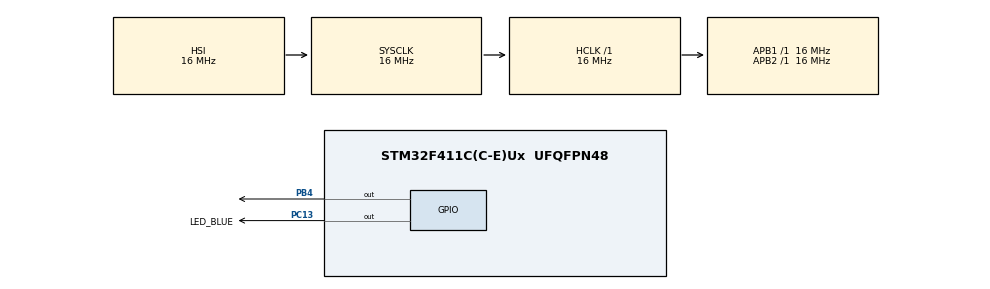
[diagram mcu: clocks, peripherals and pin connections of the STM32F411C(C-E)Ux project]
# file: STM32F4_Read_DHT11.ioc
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Mcu.Family=STM32F4
Mcu.Name=STM32F411C(C-E)Ux
Mcu.Package=UFQFPN48
NVIC.PriorityGroup=NVIC_PRIORITYGROUP_4
PA13.Mode=Serial_Wire
PA13.Signal=SYS_JTMS-SWDIO
PA14.Mode=Serial_Wire
PA14.Signal=SYS_JTCK-SWCLK
PB4.GPIO_ModeDefaultOutputPP=GPIO_MODE_OUTPUT_PP
PB4.GPIO_PuPd=GPIO_NOPULL
PB4.Signal=GPIO_Output
PC13-ANTI_TAMP.GPIO_Label=LED_BLUE
PC13-ANTI_TAMP.Signal=GPIO_Output
PH0\ -\ OSC_IN.Mode=HSE-External-Oscillator
PH0\ -\ OSC_IN.Signal=RCC_OSC_IN
PH1\ -\ OSC_OUT.Mode=HSE-External-Oscillator
PH1\ -\ OSC_OUT.Signal=RCC_OSC_OUT
ProjectManager.HeapSize=0x200
ProjectManager.StackSize=0x400
ProjectManager.TargetToolchain=STM32CubeIDE
RCC.AHBFreq_Value=16000000
RCC.APB1Freq_Value=16000000
RCC.APB2Freq_Value=16000000
RCC.CortexFreq_Value=16000000
RCC.HSE_VALUE=25000000
RCC.HSI_VALUE=16000000
RCC.LSE_VALUE=32768
RCC.SYSCLKFreq_VALUE=16000000
RCC.VCOOutputFreq_Value=192000000
TIM2.Period=0xffffffff
TIM2.Prescaler=15
VP_TIM2_VS_ClockSourceINT.Mode=Internal
board=custom

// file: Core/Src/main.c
/* USER CODE BEGIN Header */
/**
  ******************************************************************************
  * @file           : main.c
  * @brief          : Main program body
  ******************************************************************************
  * @attention
  *
  * Copyright (c) 2025 STMicroelectronics.
  * All rights reserved.
  *
  * This software is licensed under terms that can be found in the LICENSE file
  * in the root directory of this software component.
  * If no LICENSE file comes with this software, it is provided AS-IS.
  *
  ******************************************************************************
  */
/* USER CODE END Header */
#include "main.h"
#include "DHT11.h"

TIM_HandleTypeDef htim2;

/* USER CODE BEGIN PV */
volatile int32_t temperature = 0;
dht11_t dht11_sensor;
/* USER CODE END PV */

void SystemClock_Config(void);
static void MX_GPIO_Init(void);
static void MX_TIM2_Init(void);

int main(void)
{

  /* MCU Configuration--------------------------------------------------------*/

  /* Reset of all peripherals, Initializes the Flash interface and the Systick. */
  HAL_Init();

  /* Configure the system clock */
  SystemClock_Config();

  /* Initialize all configured peripherals */
  MX_GPIO_Init();
  MX_TIM2_Init();
  /* USER CODE BEGIN 2 */
  init_dht11(&dht11_sensor, &htim2, GPIOB, GPIO_PIN_4);
  HAL_TIM_Base_Start(&htim2);
  /* USER CODE END 2 */

  /* Infinite loop */
  /* USER CODE BEGIN WHILE */
  while (1)
  {
	  HAL_GPIO_WritePin(LED_BLUE_GPIO_Port, LED_BLUE_Pin, GPIO_PIN_SET);
	  HAL_Delay(200);
	  HAL_GPIO_WritePin(LED_BLUE_GPIO_Port, LED_BLUE_Pin, GPIO_PIN_RESET);
	  HAL_Delay(200);
	  // ReaD DHT11
	  if (readDHT11(&dht11_sensor)) {
		// Lưu giá trị nhiệt độ vào biến global
		temperature = dht11_sensor.temperature;

		// Bạn có thể thêm một đoạn code để gửi giá trị đi (ví dụ qua UART, hiển thị trên LCD, v.v.)
		// Ví dụ:
		// sprintf(buf, "Temperature: %d C", temperature);
		// HAL_UART_Transmit(&huart1, (uint8_t*)buf, strlen(buf), HAL_MAX_DELAY);
	  }

	  HAL_GPIO_WritePin(LED_BLUE_GPIO_Port, LED_BLUE_Pin, GPIO_PIN_SET);
	  HAL_Delay(200);
	  HAL_GPIO_WritePin(LED_BLUE_GPIO_Port, LED_BLUE_Pin, GPIO_PIN_RESET);
	  HAL_Delay(200);
	  HAL_Delay(3000);

    /* USER CODE END WHILE */

  }
}

void SystemClock_Config(void)
{
  RCC_OscInitTypeDef RCC_OscInitStruct = {0};
  RCC_ClkInitTypeDef RCC_ClkInitStruct = {0};

  /** Configure the main internal regulator output voltage
  */
  __HAL_RCC_PWR_CLK_ENABLE();
  __HAL_PWR_VOLTAGESCALING_CONFIG(PWR_REGULATOR_VOLTAGE_SCALE1);

  /** Initializes the RCC Oscillators according to the specified parameters
  * in the RCC_OscInitTypeDef structure.
  */
  RCC_OscInitStruct.OscillatorType = RCC_OSCILLATORTYPE_HSI;
  RCC_OscInitStruct.HSIState = RCC_HSI_ON;
  RCC_OscInitStruct.HSICalibrationValue = RCC_HSICALIBRATION_DEFAULT;
  RCC_OscInitStruct.PLL.PLLState = RCC_PLL_NONE;
  if (HAL_RCC_OscConfig(&RCC_OscInitStruct) != HAL_OK)
  {
    Error_Handler();
  }

  /** Initializes the CPU, AHB and APB buses clocks
  */
  RCC_ClkInitStruct.ClockType = RCC_CLOCKTYPE_HCLK|RCC_CLOCKTYPE_SYSCLK
                              |RCC_CLOCKTYPE_PCLK1|RCC_CLOCKTYPE_PCLK2;
  RCC_ClkInitStruct.SYSCLKSource = RCC_SYSCLKSOURCE_HSI;
  RCC_ClkInitStruct.AHBCLKDivider = RCC_SYSCLK_DIV1;
  RCC_ClkInitStruct.APB1CLKDivider = RCC_HCLK_DIV1;
  RCC_ClkInitStruct.APB2CLKDivider = RCC_HCLK_DIV1;

  if (HAL_RCC_ClockConfig(&RCC_ClkInitStruct, FLASH_LATENCY_0) != HAL_OK)
  {
    Error_Handler();
  }
}

static void MX_TIM2_Init(void)
{

  TIM_ClockConfigTypeDef sClockSourceConfig = {0};
  TIM_MasterConfigTypeDef sMasterConfig = {0};

  htim2.Instance = TIM2;
  htim2.Init.Prescaler = 15;
  htim2.Init.CounterMode = TIM_COUNTERMODE_UP;
  htim2.Init.Period = 0xffffffff;
  htim2.Init.ClockDivision = TIM_CLOCKDIVISION_DIV1;
  htim2.Init.AutoReloadPreload = TIM_AUTORELOAD_PRELOAD_DISABLE;
  if (HAL_TIM_Base_Init(&htim2) != HAL_OK)
  {
    Error_Handler();
  }
  sClockSourceConfig.ClockSource = TIM_CLOCKSOURCE_INTERNAL;
  if (HAL_TIM_ConfigClockSource(&htim2, &sClockSourceConfig) != HAL_OK)
  {
    Error_Handler();
  }
  sMasterConfig.MasterOutputTrigger = TIM_TRGO_RESET;
  sMasterConfig.MasterSlaveMode = TIM_MASTERSLAVEMODE_DISABLE;
  if (HAL_TIMEx_MasterConfigSynchronization(&htim2, &sMasterConfig) != HAL_OK)
  {
    Error_Handler();
  }

}

static void MX_GPIO_Init(void)
{
  GPIO_InitTypeDef GPIO_InitStruct = {0};

  /* GPIO Ports Clock Enable */
  __HAL_RCC_GPIOC_CLK_ENABLE();
  __HAL_RCC_GPIOH_CLK_ENABLE();
  __HAL_RCC_GPIOA_CLK_ENABLE();
  __HAL_RCC_GPIOB_CLK_ENABLE();

  /*Configure GPIO pin Output Level */
  HAL_GPIO_WritePin(LED_BLUE_GPIO_Port, LED_BLUE_Pin, GPIO_PIN_RESET);

  /*Configure GPIO pin Output Level */
  HAL_GPIO_WritePin(GPIOB, GPIO_PIN_4, GPIO_PIN_RESET);

  /*Configure GPIO pin : LED_BLUE_Pin */
  GPIO_InitStruct.Pin = LED_BLUE_Pin;
  GPIO_InitStruct.Mode = GPIO_MODE_OUTPUT_PP;
  GPIO_InitStruct.Pull = GPIO_NOPULL;
  GPIO_InitStruct.Speed = GPIO_SPEED_FREQ_LOW;
  HAL_GPIO_Init(LED_BLUE_GPIO_Port, &GPIO_InitStruct);

  /*Configure GPIO pin : PB4 */
  GPIO_InitStruct.Pin = GPIO_PIN_4;
  GPIO_InitStruct.Mode = GPIO_MODE_OUTPUT_PP;
  GPIO_InitStruct.Pull = GPIO_NOPULL;
  GPIO_InitStruct.Speed = GPIO_SPEED_FREQ_LOW;
  HAL_GPIO_Init(GPIOB, &GPIO_InitStruct);

}

void Error_Handler(void)
{
  __disable_irq();
  while (1)
  {
  }
}
